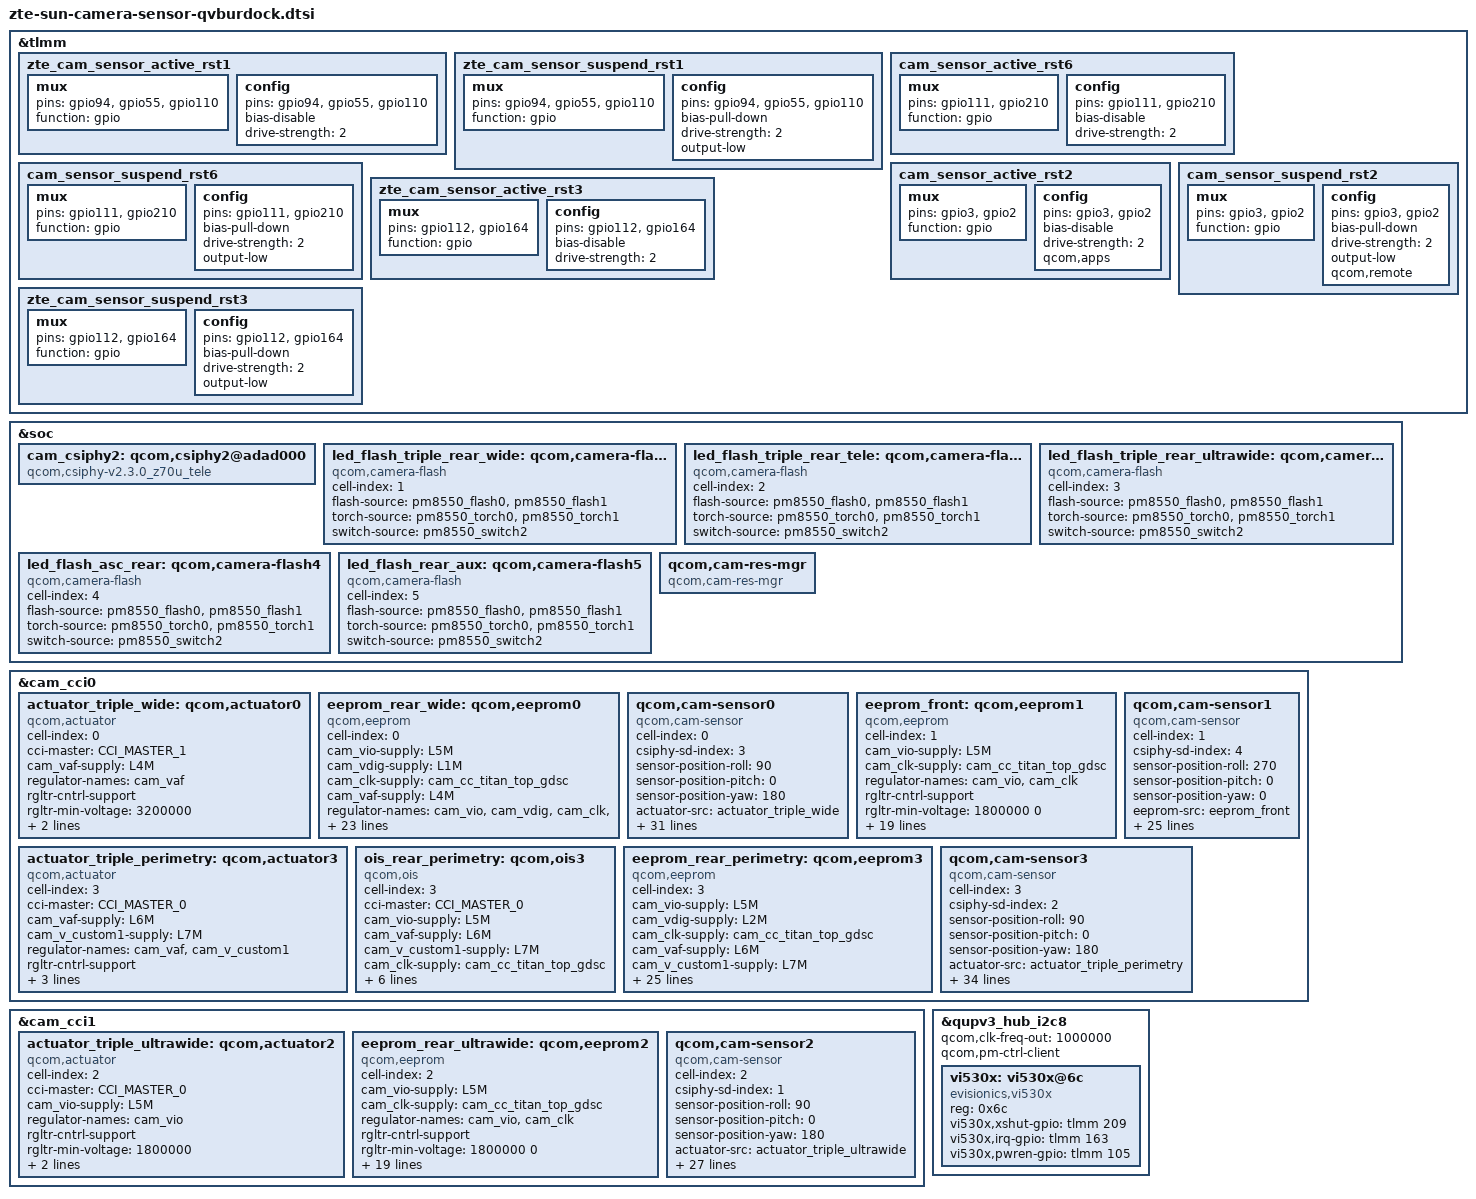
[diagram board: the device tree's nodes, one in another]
#include <dt-bindings/msm-camera.h>
&tlmm {
	zte_cam_sensor_active_rst1: zte_cam_sensor_active_rst1 {
		/* RESET 2 */
		mux {
			pins = "gpio94", "gpio55", "gpio110";
			function = "gpio";
		};

		config {
			pins = "gpio94", "gpio55", "gpio110";
			bias-disable; /* No PULL */
			drive-strength = <2>; /* 2 MA */
		};
	};

	zte_cam_sensor_suspend_rst1: zte_cam_sensor_suspend_rst1 {
		/* RESET 2 */
		mux {
			pins = "gpio94", "gpio55", "gpio110";
			function = "gpio";
		};

		config {
			pins = "gpio94", "gpio55", "gpio110";
			bias-pull-down; /* PULL DOWN */
			drive-strength = <2>; /* 2 MA */
			output-low;
		};
	};

	cam_sensor_active_rst6: cam_sensor_active_rst6 {
		/* RESET 2 */
		mux {
			pins = "gpio111", "gpio210";
			function = "gpio";
		};

		config {
			pins = "gpio111", "gpio210";
			bias-disable; /* No PULL */
			drive-strength = <2>; /* 2 MA */
		};
	};

	cam_sensor_suspend_rst6: cam_sensor_suspend_rst6 {
		/* RESET 2 */
		mux {
			pins = "gpio111", "gpio210";
			function = "gpio";
		};

		config {
			pins = "gpio111", "gpio210";
			bias-pull-down; /* PULL DOWN */
			drive-strength = <2>; /* 2 MA */
			output-low;
		};
	};

	cam_sensor_active_rst2: cam_sensor_active_rst2 {
		mux {
			pins = "gpio3", "gpio2";
			function = "gpio";
		};

		config {
			pins = "gpio3", "gpio2";
			bias-disable; /* No PULL */
			drive-strength = <2>; /* 2 MA */
			qcom,apps;
		};
	};

	cam_sensor_suspend_rst2: cam_sensor_suspend_rst2 {
		mux {
			pins = "gpio3", "gpio2";
			function = "gpio";
		};

		config {
			pins = "gpio3", "gpio2";
			bias-pull-down; /* PULL DOWN */
			drive-strength = <2>; /* 2 MA */
			output-low;
			qcom,remote;
		};
	};

	zte_cam_sensor_active_rst3: zte_cam_sensor_active_rst3 {
		/* RESET 2 */
		mux {
			pins = "gpio112", "gpio164";
			function = "gpio";
		};

		config {
			pins = "gpio112", "gpio164";
			bias-disable; /* No PULL */
			drive-strength = <2>; /* 2 MA */
		};
	};

	zte_cam_sensor_suspend_rst3: zte_cam_sensor_suspend_rst3 {
		/* RESET 2 */
		mux {
			pins = "gpio112", "gpio164";
			function = "gpio";
		};

		config {
			pins = "gpio112", "gpio164";
			bias-pull-down; /* PULL DOWN */
			drive-strength = <2>; /* 2 MA */
			output-low;
		};
	};
};

&soc {
 	cam_csiphy2: qcom,csiphy2@adad000 {
 		compatible = "qcom,csiphy-v2.3.0_z70u_tele", "qcom,csiphy";
 	};

	led_flash_triple_rear_wide: qcom,camera-flash1 {
		cell-index = <1>;
		compatible = "qcom,camera-flash";
		flash-source = <&pm8550_flash0 &pm8550_flash1>;
		torch-source = <&pm8550_torch0 &pm8550_torch1>;
		switch-source = <&pm8550_switch2>;
		status = "ok";
	};

	led_flash_triple_rear_tele: qcom,camera-flash2 {
		cell-index = <2>;
		compatible = "qcom,camera-flash";
		flash-source = <&pm8550_flash0 &pm8550_flash1>;
		torch-source = <&pm8550_torch0 &pm8550_torch1>;
		switch-source = <&pm8550_switch2>;
		status = "ok";
	};

	led_flash_triple_rear_ultrawide: qcom,camera-flash3 {
		cell-index = <3>;
		compatible = "qcom,camera-flash";
		flash-source = <&pm8550_flash0 &pm8550_flash1>;
		torch-source = <&pm8550_torch0 &pm8550_torch1>;
		switch-source = <&pm8550_switch2>;
		status = "ok";
	};

	led_flash_asc_rear: qcom,camera-flash4 {
		cell-index = <4>;
		compatible = "qcom,camera-flash";
		flash-source = <&pm8550_flash0 &pm8550_flash1>;
		torch-source = <&pm8550_torch0 &pm8550_torch1>;
		switch-source = <&pm8550_switch2>;
		status = "ok";
	};

	led_flash_rear_aux: qcom,camera-flash5 {
		cell-index = <5>;
		compatible = "qcom,camera-flash";
		flash-source = <&pm8550_flash0 &pm8550_flash1>;
		torch-source = <&pm8550_torch0 &pm8550_torch1>;
		switch-source = <&pm8550_switch2>;
		status = "ok";
	};

	qcom,cam-res-mgr {
		compatible = "qcom,cam-res-mgr";
		status = "ok";
	};
};

&cam_cci0 {
	actuator_triple_wide: qcom,actuator0 {
		cell-index = <0>;
		compatible = "qcom,actuator";
		cci-master = <CCI_MASTER_1>;
		cam_vaf-supply = <&L4M>;
		regulator-names = "cam_vaf";
		rgltr-cntrl-support;
		rgltr-min-voltage = <3200000>;
		rgltr-max-voltage = <3200000>;
		rgltr-load-current = <67700>;
	};

	eeprom_rear_wide: qcom,eeprom0 {
		cell-index = <0>;
		compatible = "qcom,eeprom";
		cam_vio-supply = <&L5M>;
		cam_vdig-supply = <&L1M>;
		cam_clk-supply = <&cam_cc_titan_top_gdsc>;
		cam_vaf-supply = <&L4M>;
		regulator-names = "cam_vio", "cam_vdig", "cam_clk", "cam_vaf";
		rgltr-cntrl-support;
		rgltr-min-voltage = <1800000 1200000 0 3200000>;
		rgltr-max-voltage = <1800000 1200000 0 3200000>;
		rgltr-load-current = <155000 680000 0 67700>;
		gpio-no-mux = <0>;
		pinctrl-names = "cam_default", "cam_suspend";
		pinctrl-0 = <&cam_sensor_mclk1_active
			&zte_cam_sensor_active_rst1>;
		pinctrl-1 = <&cam_sensor_mclk1_suspend
			&zte_cam_sensor_suspend_rst1>;
		gpios = <&tlmm 90 0>,
			<&tlmm 94 0>,
			<&tlmm 55 0>,
			<&tlmm 110 0>;
		gpio-reset = <1>;
		gpio-custom1 = <2>;
		gpio-custom2 = <3>;
		gpio-req-tbl-num = <0 1 2 3>;
		gpio-req-tbl-flags = <1 0 0 0>;
		gpio-req-tbl-label = "CAMIF_MCLK1",
					"CAM_RESET1",
					"CAM_VANA1",
					"CAM_VDR1";
		cci-master = <CCI_MASTER_1>;
		clocks = <&cambistmclkcc CAM_BIST_MCLK_CC_MCLK1_CLK>;
		clock-names = "cam_clk";
		clock-cntl-level = "nominal";
		clock-rates = <24000000>;
		status = "ok";
	};

	qcom,cam-sensor0 {
		cell-index = <0>;
		compatible = "qcom,cam-sensor";
		csiphy-sd-index = <3>;
		sensor-position-roll = <90>;
		sensor-position-pitch = <0>;
		sensor-position-yaw = <180>;
		actuator-src = <&actuator_triple_wide>;
		led-flash-src = <&led_flash_triple_rear_wide>;
		eeprom-src = <&eeprom_rear_wide>;
		cam_vio-supply = <&L5M>;
		cam_vdig-supply = <&L1M>;
		cam_clk-supply = <&cam_cc_titan_top_gdsc>;
		cam_vaf-supply = <&L4M>;
		regulator-names = "cam_vio", "cam_vdig", "cam_clk", "cam_vaf";
		rgltr-cntrl-support;
		rgltr-min-voltage = <1800000 1200000 0 3200000>;
		rgltr-max-voltage = <1800000 1200000 0 3200000>;
		rgltr-load-current = <155000 680000 0 67700>;
		gpio-no-mux = <0>;
		pinctrl-names = "cam_default", "cam_suspend";
		pinctrl-0 = <&cam_sensor_mclk1_active
			&zte_cam_sensor_active_rst1>;
		pinctrl-1 = <&cam_sensor_mclk1_suspend
			&zte_cam_sensor_suspend_rst1>;
		gpios = <&tlmm 90 0>,
			<&tlmm 94 0>,
			<&tlmm 55 0>,
			<&tlmm 110 0>;
		gpio-reset = <1>;
		gpio-custom1 = <2>;
		gpio-custom2 = <3>;
		gpio-req-tbl-num = <0 1 2 3>;
		gpio-req-tbl-flags = <1 0 0 0>;
		gpio-req-tbl-label = "CAMIF_MCLK1",
					"CAM_RESET1",
					"CAM_VANA1",
					"CAM_VDR1";
		cci-master = <CCI_MASTER_1>;
		clocks = <&cambistmclkcc CAM_BIST_MCLK_CC_MCLK1_CLK>;
		clock-names = "cam_clk";
		clock-cntl-level = "nominal";
		clock-rates = <24000000>;
		status = "ok";
		zte-tof-enable;
	};

	eeprom_front: qcom,eeprom1 {
		cell-index = <1>;
		compatible = "qcom,eeprom";
		cam_vio-supply = <&L5M>;
		cam_clk-supply = <&cam_cc_titan_top_gdsc>;
		regulator-names = "cam_vio", "cam_clk";
		rgltr-cntrl-support;
		rgltr-min-voltage = <1800000 0>;
		rgltr-max-voltage = <1800000 0>;
		rgltr-load-current = <4000 0>;
		gpio-no-mux = <0>;
		pinctrl-names = "cam_default", "cam_suspend";
		pinctrl-0 = <&cam_sensor_mclk4_active
				 &cam_sensor_active_rst6>;
		pinctrl-1 = <&cam_sensor_mclk4_suspend
				 &cam_sensor_suspend_rst6>;
		gpios = <&tlmm 93 0>,
			<&tlmm 111 0>,
			<&tlmm 210 0>;
		gpio-reset = <1>;
		gpio-custom1 = <2>;
		gpio-req-tbl-num = <0 1 2>;
		gpio-req-tbl-flags = <1 0 0>;
		gpio-req-tbl-label = "CAMIF_MCLK4",
					"CAM_RESET6",
					"CAM_VANA6";
		cci-master = <CCI_MASTER_0>;
		clocks = <&cambistmclkcc CAM_BIST_MCLK_CC_MCLK4_CLK>;
		clock-names = "cam_clk";
		clock-cntl-level = "nominal";
		clock-rates = <24000000>;
		status = "ok";
	};

	qcom,cam-sensor1 {
		cell-index = <1>;
		compatible = "qcom,cam-sensor";
		csiphy-sd-index = <4>;
		sensor-position-roll = <270>;
		sensor-position-pitch = <0>;
		sensor-position-yaw = <0>;
		eeprom-src = <&eeprom_front>;
		cam_vio-supply = <&L5M>;
		cam_clk-supply = <&cam_cc_titan_top_gdsc>;
		regulator-names = "cam_vio", "cam_clk";
		rgltr-cntrl-support;
		rgltr-min-voltage = <1800000 0>;
		rgltr-max-voltage = <1800000 0>;
		rgltr-load-current = <4000 0>;
		gpio-no-mux = <0>;
		pinctrl-names = "cam_default", "cam_suspend";
		pinctrl-0 = <&cam_sensor_mclk4_active
				 &cam_sensor_active_rst6>;
		pinctrl-1 = <&cam_sensor_mclk4_suspend
				 &cam_sensor_suspend_rst6>;
		gpios = <&tlmm 93 0>,
			<&tlmm 111 0>,
			<&tlmm 210 0>;
		gpio-reset = <1>;
		gpio-custom1 = <2>;
		gpio-req-tbl-num = <0 1 2>;
		gpio-req-tbl-flags = <1 0 0>;
		gpio-req-tbl-label = "CAMIF_MCLK4",
					"CAM_RESET6",
					"CAM_VANA6";
		cci-master = <CCI_MASTER_0>;
		clocks = <&cambistmclkcc CAM_BIST_MCLK_CC_MCLK4_CLK>;
		clock-names = "cam_clk";
		clock-cntl-level = "nominal";
		clock-rates = <24000000>;
		status = "ok";
		zte-tof-enable;
	};

	actuator_triple_perimetry: qcom,actuator3 {
		cell-index = <3>;
		compatible = "qcom,actuator";
		cci-master = <CCI_MASTER_0>;
		cam_vaf-supply = <&L6M>;
		cam_v_custom1-supply = <&L7M>;
		regulator-names = "cam_vaf", "cam_v_custom1";
		rgltr-cntrl-support;
		rgltr-min-voltage = <2800000 2800000>;
		rgltr-max-voltage = <2800000 2800000>;
		rgltr-load-current = <91400 119000>;
	};

	ois_rear_perimetry: qcom,ois3 {
		cell-index = <3>;
		compatible = "qcom,ois";
		cci-master = <CCI_MASTER_0>;
		cam_vio-supply = <&L5M>;
		cam_vaf-supply = <&L6M>;
		cam_v_custom1-supply = <&L7M>;
		cam_clk-supply = <&cam_cc_titan_top_gdsc>;
		regulator-names = "cam_vio","cam_vaf", "cam_v_custom1", "cam_clk";
		rgltr-cntrl-support;
		rgltr-min-voltage = <1800000 2800000 2800000 0>;
		rgltr-max-voltage = <1800000 2800000 2800000 0>;
		rgltr-load-current = <4000 119000 119000 0>;
		status = "ok";
	};

	eeprom_rear_perimetry: qcom,eeprom3 {
		cell-index = <3>;
		compatible = "qcom,eeprom";
		cam_vio-supply = <&L5M>;
		cam_vdig-supply = <&L2M>;
		cam_clk-supply = <&cam_cc_titan_top_gdsc>;
		cam_vaf-supply = <&L6M>;
		cam_v_custom1-supply = <&L7M>;
		regulator-names = "cam_vio", "cam_vdig", "cam_clk", "cam_vaf", "cam_v_custom1";
		rgltr-cntrl-support;
		rgltr-min-voltage = <1800000 1100000 0 2800000 2800000>;
		rgltr-max-voltage = <1800000 1100000 0 2800000 2800000>;
		rgltr-load-current = <4000 260700 0 91400 119000>;
		gpio-no-mux = <0>;
		pinctrl-names = "cam_default", "cam_suspend";
		pinctrl-0 = <&cam_sensor_mclk3_active
				 &zte_cam_sensor_active_rst3>;
		pinctrl-1 = <&cam_sensor_mclk3_suspend
				 &zte_cam_sensor_suspend_rst3>;
		gpios = <&tlmm 92 0>,
			<&tlmm 112 0>,
			<&tlmm 164 0>;
		gpio-reset = <1>;
		gpio-custom1 = <2>;
		gpio-req-tbl-num = <0 1 2>;
		gpio-req-tbl-flags = <1 0 0>;
		gpio-req-tbl-label = "CAMIF_MCLK3",
					"CAM_RESET3",
					"CAM_VANA3";
		cci-master = <CCI_MASTER_0>;
		clocks = <&cambistmclkcc CAM_BIST_MCLK_CC_MCLK3_CLK>;
		clock-names = "cam_clk";
		clock-cntl-level = "nominal";
		clock-rates = <24000000>;
		status = "ok";
	};

	qcom,cam-sensor3 {
		cell-index = <3>;
		compatible = "qcom,cam-sensor";
		csiphy-sd-index = <2>;
		sensor-position-roll = <90>;
		sensor-position-pitch = <0>;
		sensor-position-yaw = <180>;
		actuator-src = <&actuator_triple_perimetry>;
		led-flash-src = <&led_flash_triple_rear_tele>;
		eeprom-src = <&eeprom_rear_perimetry>;
		ois-src = <&ois_rear_perimetry>;
		cam_vio-supply = <&L5M>;
		cam_vdig-supply = <&L2M>;
		cam_clk-supply = <&cam_cc_titan_top_gdsc>;
		cam_vaf-supply = <&L6M>;
		cam_v_custom1-supply = <&L7M>;
		regulator-names = "cam_vio", "cam_vdig", "cam_clk", "cam_vaf", "cam_v_custom1";
		rgltr-cntrl-support;
		rgltr-min-voltage = <1800000 1100000 0 2800000 2800000>;
		rgltr-max-voltage = <1800000 1100000 0 2800000 2800000>;
		rgltr-load-current = <4000 260700 0 91400 119000>;
		gpio-no-mux = <0>;
		pinctrl-names = "cam_default", "cam_suspend";
		pinctrl-0 = <&cam_sensor_mclk3_active
				 &zte_cam_sensor_active_rst3>;
		pinctrl-1 = <&cam_sensor_mclk3_suspend
				 &zte_cam_sensor_suspend_rst3>;
		gpios = <&tlmm 92 0>,
			<&tlmm 112 0>,
			<&tlmm 164 0>;
		gpio-reset = <1>;
		gpio-custom1 = <2>;
		gpio-req-tbl-num = <0 1 2>;
		gpio-req-tbl-flags = <1 0 0>;
		gpio-req-tbl-label = "CAMIF_MCLK3",
					"CAM_RESET3",
					"CAM_VANA3";
		cci-master = <CCI_MASTER_0>;
		clocks = <&cambistmclkcc CAM_BIST_MCLK_CC_MCLK3_CLK>;
		clock-names = "cam_clk";
		clock-cntl-level = "nominal";
		clock-rates = <24000000>;
		status = "ok";
		zte-tof-enable;
	};
};

&cam_cci1 {
	actuator_triple_ultrawide: qcom,actuator2 {
		cell-index = <2>;
		compatible = "qcom,actuator";
		cci-master = <CCI_MASTER_0>;
		cam_vio-supply = <&L5M>;
		regulator-names = "cam_vio";
		rgltr-cntrl-support;
		rgltr-min-voltage = <1800000>;
		rgltr-max-voltage = <1800000>;
		rgltr-load-current = <4000>;
	};

	eeprom_rear_ultrawide: qcom,eeprom2 {
		cell-index = <2>;
		compatible = "qcom,eeprom";
		cam_vio-supply = <&L5M>;
		cam_clk-supply = <&cam_cc_titan_top_gdsc>;
		regulator-names = "cam_vio", "cam_clk";
		rgltr-cntrl-support;
		rgltr-min-voltage = <1800000 0>;
		rgltr-max-voltage = <1800000 0>;
		rgltr-load-current = <4000 0>;
		gpio-no-mux = <0>;
		pinctrl-names = "cam_default", "cam_suspend";
		pinctrl-0 = <&cam_sensor_mclk2_active
				 &cam_sensor_active_rst2>;
		pinctrl-1 = <&cam_sensor_mclk2_suspend
				 &cam_sensor_suspend_rst2>;
		gpios = <&tlmm 91 0>,
			<&tlmm 3 0>,
			<&tlmm 2 0>;
		gpio-reset = <1>;
		gpio-custom1 = <2>;
		gpio-req-tbl-num = <0 1 2>;
		gpio-req-tbl-flags = <1 0 0>;
		gpio-req-tbl-label = "CAMIF_MCLK2",
					"CAM_RESET2",
					"CAM_VANA2";
		cci-master = <CCI_MASTER_0>;
		clocks = <&cambistmclkcc CAM_BIST_MCLK_CC_MCLK2_CLK>;
		clock-names = "cam_clk";
		clock-cntl-level = "nominal";
		clock-rates = <24000000>;
		status = "ok";
	};

	qcom,cam-sensor2 {
		cell-index = <2>;
		compatible = "qcom,cam-sensor";
		csiphy-sd-index = <1>;
		sensor-position-roll = <90>;
		sensor-position-pitch = <0>;
		sensor-position-yaw = <180>;
		actuator-src = <&actuator_triple_ultrawide>;
		led-flash-src = <&led_flash_triple_rear_ultrawide>;
		eeprom-src = <&eeprom_rear_ultrawide>;
		cam_vio-supply = <&L5M>;
		cam_clk-supply = <&cam_cc_titan_top_gdsc>;
		regulator-names = "cam_vio", "cam_clk";
		rgltr-cntrl-support;
		rgltr-min-voltage = <1800000 0>;
		rgltr-max-voltage = <1800000 0>;
		rgltr-load-current = <4000 0>;
		gpio-no-mux = <0>;
		pinctrl-names = "cam_default", "cam_suspend";
		pinctrl-0 = <&cam_sensor_mclk2_active
				 &cam_sensor_active_rst2>;
		pinctrl-1 = <&cam_sensor_mclk2_suspend
				 &cam_sensor_suspend_rst2>;
		gpios = <&tlmm 91 0>,
			<&tlmm 3 0>,
			<&tlmm 2 0>;
		gpio-reset = <1>;
		gpio-custom1 = <2>;
		gpio-req-tbl-num = <0 1 2>;
		gpio-req-tbl-flags = <1 0 0>;
		gpio-req-tbl-label = "CAMIF_MCLK2",
					"CAM_RESET2",
					"CAM_VANA2";
		cci-master = <CCI_MASTER_0>;
		clocks = <&cambistmclkcc CAM_BIST_MCLK_CC_MCLK2_CLK>;
		clock-names = "cam_clk";
		clock-cntl-level = "nominal";
		clock-rates = <24000000>;
		status = "ok";
		zte-tof-enable;
	};
};

&qupv3_hub_i2c8 {
	status = "ok";
	qcom,clk-freq-out = <1000000>;
	qcom,pm-ctrl-client;
	vi530x: vi530x@6c{
		reg = <0x6c>;
		compatible = "evisionics,vi530x";
		vi530x,xshut-gpio = <&tlmm 209 0>;  //RESET
		vi530x,irq-gpio = <&tlmm 163 0>;    //INT
		vi530x,pwren-gpio = <&tlmm 105 0>;  //VDD
		status = "ok";
	};
};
